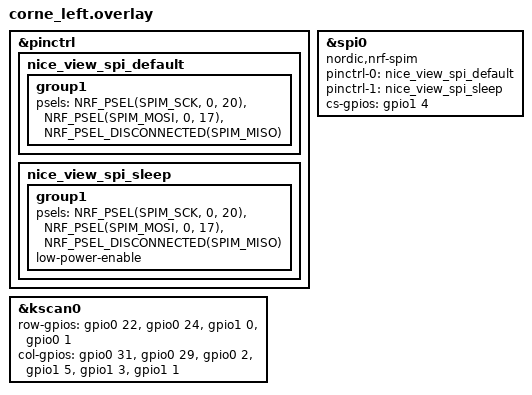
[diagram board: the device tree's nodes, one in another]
#include <zephyr/dt-bindings/pinctrl/nrf-pinctrl.h>

/* Pinctrl setup for the SPIM instance we’ll use for nice!view */
&pinctrl {
    nice_view_spi_default: nice_view_spi_default {
        group1 {
            psels = <NRF_PSEL(SPIM_SCK, 0, 20)>,
                    <NRF_PSEL(SPIM_MOSI, 0, 17)>,
                    <NRF_PSEL_DISCONNECTED(SPIM_MISO)>;
        };
    };

    nice_view_spi_sleep: nice_view_spi_sleep {
        group1 {
            psels = <NRF_PSEL(SPIM_SCK, 0, 20)>,
                    <NRF_PSEL(SPIM_MOSI, 0, 17)>,
                    <NRF_PSEL_DISCONNECTED(SPIM_MISO)>;
            low-power-enable;
        };
    };
};

/*
 * Provide the label the nice_view_gem overlay expects:
 * &nice_view_spi
 *
 * We point it at spi0 (SPIM0). If your board already uses spi0 for something,
 * switch this to &spi1 instead.
 */
nice_view_spi: &spi0 {
    status = "okay";
    compatible = "nordic,nrf-spim";

    pinctrl-0 = <&nice_view_spi_default>;
    pinctrl-1 = <&nice_view_spi_sleep>;
    pinctrl-names = "default", "sleep";

    // cs pin traced to pin D8, 1.04
    cs-gpios = <&gpio1 4 GPIO_ACTIVE_HIGH>;
};

&kscan0 {
    row-gpios
        = <&gpio0 22 (GPIO_ACTIVE_HIGH | GPIO_PULL_DOWN)>
        , <&gpio0 24 (GPIO_ACTIVE_HIGH | GPIO_PULL_DOWN)>
        , <&gpio1  0 (GPIO_ACTIVE_HIGH | GPIO_PULL_DOWN)>
        , <&gpio0  1 (GPIO_ACTIVE_HIGH | GPIO_PULL_DOWN)>
        ;

    col-gpios
        = <&gpio0  31 GPIO_ACTIVE_HIGH>
        , <&gpio0  29 GPIO_ACTIVE_HIGH>
        , <&gpio0  2 GPIO_ACTIVE_HIGH>
        , <&gpio1  5 GPIO_ACTIVE_HIGH>
        , <&gpio1  3 GPIO_ACTIVE_HIGH>
        , <&gpio1  1 GPIO_ACTIVE_HIGH>
        ;
};
